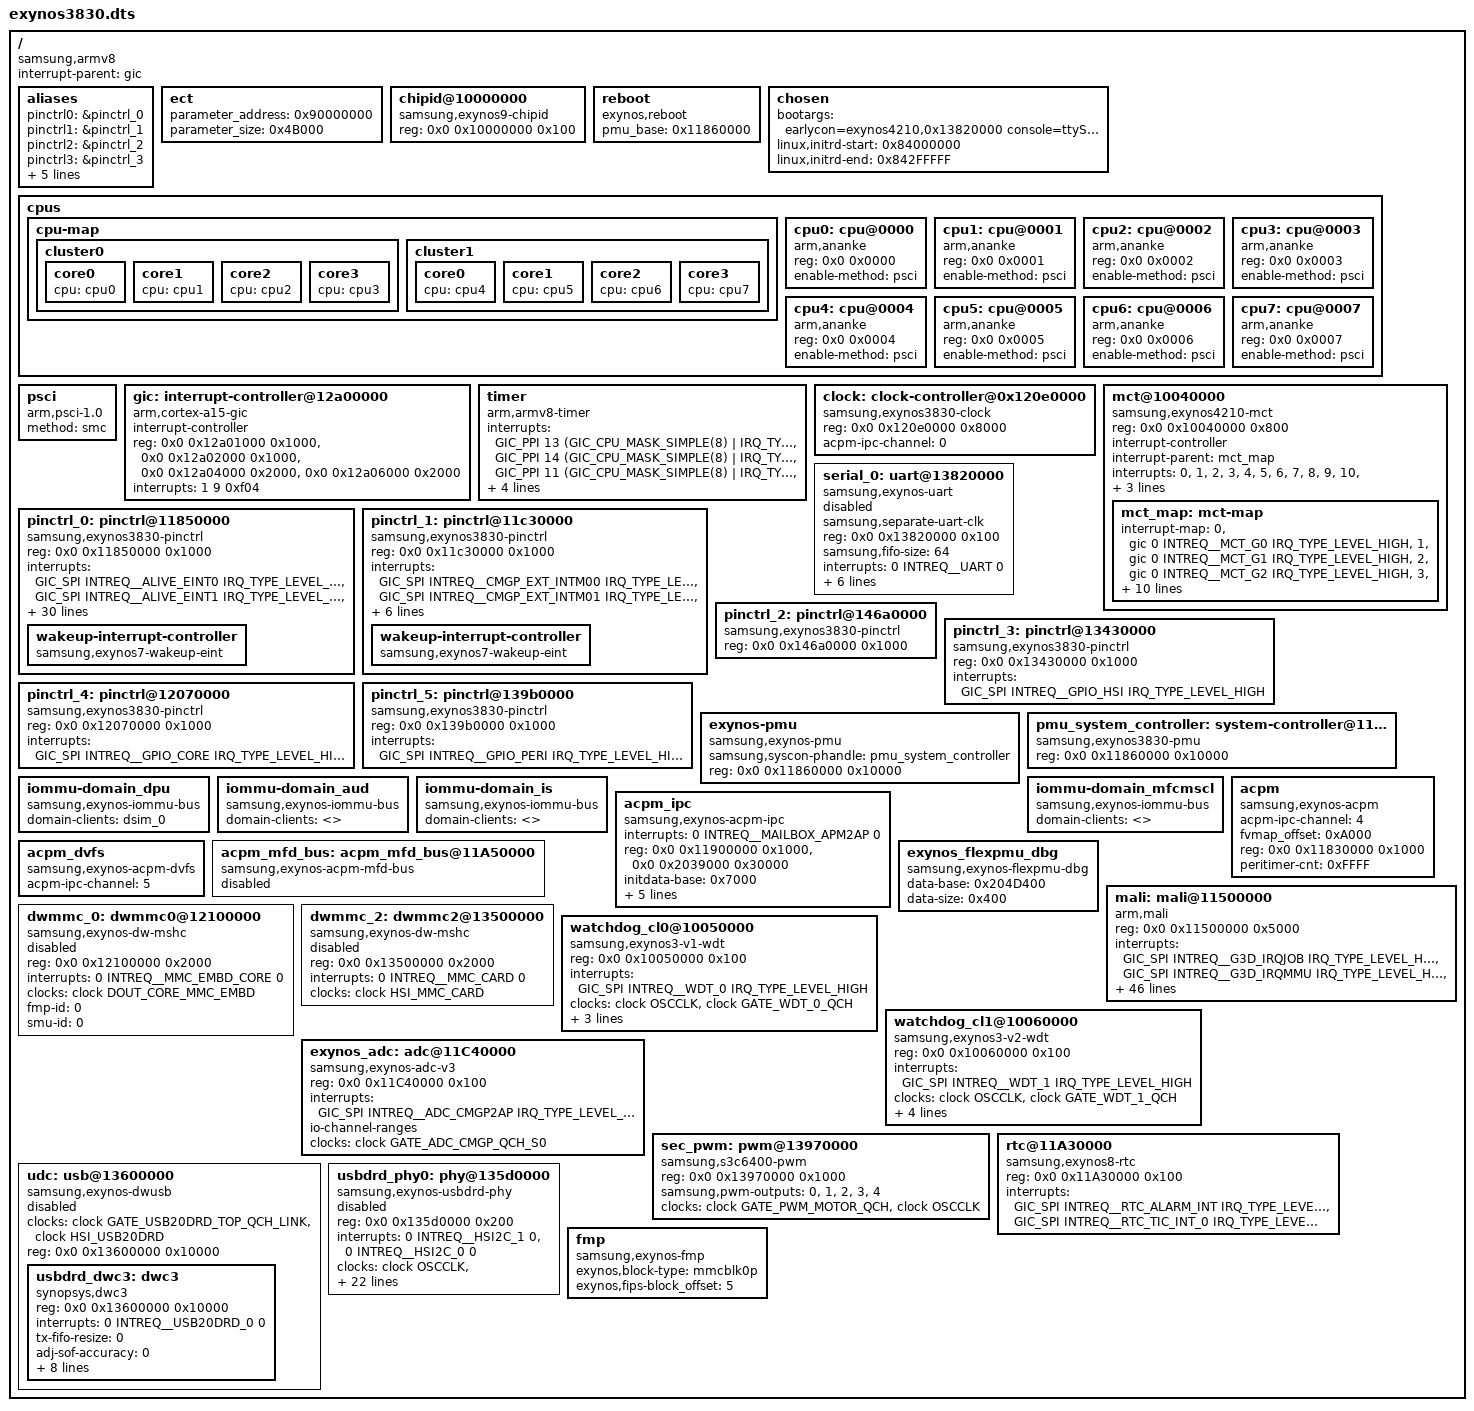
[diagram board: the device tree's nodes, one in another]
/*
 * SAMSUNG EXYNOS3830 SoC device tree source
 *
 * Copyright (c) 2018 Samsung Electronics Co., Ltd.
 *		http://www.samsung.com
 *
 * SAMSUNG EXYNOS3830 SoC device nodes are listed in this file.
 * EXYNOS based board files can include this file and provide
 * values for board specfic bindings.
 *
 * This program is free software; you can redistribute it and/or modify
 * it under the terms of the GNU General Public License version 2 as
 * published by the Free Software Foundation.
 */

/dts-v1/;
#include <dt-bindings/interrupt-controller/arm-gic.h>
#include <dt-bindings/interrupt-controller/exynos3830.h>
#include <dt-bindings/clock/exynos3830.h>
#include "exynos3830-pinctrl.dtsi"
#include "exynos3830-rmem.dtsi"
#include "exynos3830-sysmmu.dtsi"
#include "exynos3830-dpu.dtsi"
#include "exynos3830-usi.dtsi"
#include "exynos3830-debug.dtsi"
#include "exynos3830-pm-domains.dtsi"

/ {
	compatible = "samsung,armv8", "samsung,exynos3830";
	interrupt-parent = <&gic>;
	#address-cells = <2>;
	#size-cells = <1>;

	aliases {
		pinctrl0 = &pinctrl_0;
		pinctrl1 = &pinctrl_1;
		pinctrl2 = &pinctrl_2;
		pinctrl3 = &pinctrl_3;
		pinctrl4 = &pinctrl_4;
		pinctrl5 = &pinctrl_5;
		uart0 = &serial_0;
		mshc0 = &dwmmc_0;
		mshc2 = &dwmmc_2;

	};

	ect {
		parameter_address = <0x90000000>;
		parameter_size = <0x4B000>;
	};

	chipid@10000000 {
		compatible = "samsung,exynos9-chipid";
		reg = <0x0 0x10000000 0x100>;
	};

	reboot {
		compatible = "exynos,reboot";
		pmu_base = <0x11860000>;
	};

	chosen: chosen {
		bootargs = "earlycon=exynos4210,0x13820000 console=ttySAC0,115200n8 androidboot.dtbo_idx=0 skip_initramfs rootwait ro root=/dev/mmcblk0p12 init=/init clk_ignore_unused androidboot.hardware=exynos3830 androidboot.debug_level=0x4948 firmware_class.path=/vendor/firmware";
		//bootargs = "earlycon=exynos4210,0x13820000 console=ttySAC0,115200n8 androidboot.dtbo_idx=0 root=/dev/ram0 rw ramdisk=8192 initrd=0x84000000,8M init=/linuxrc mem=512M clk_ignore_unused";
		linux,initrd-start = <0x84000000>;
		linux,initrd-end = <0x842FFFFF>;
	};

	cpus {
		#address-cells = <2>;
		#size-cells = <0>;

		cpu-map {
			cluster0 {
				core0 {
					cpu = <&cpu0>;
				};
				core1 {
					cpu = <&cpu1>;
				};
				core2 {
					cpu = <&cpu2>;
				};
				core3 {
					cpu = <&cpu3>;
				};
			};

			cluster1 {
				core0 {
					cpu = <&cpu4>;
				};
				core1 {
					cpu = <&cpu5>;
				};
				core2 {
					cpu = <&cpu6>;
				};
				core3 {
					cpu = <&cpu7>;
				};
			};
		};

		cpu0: cpu@0000 {
			device_type = "cpu";
			compatible = "arm,ananke", "arm,armv8";
			reg = <0x0 0x0000>;
			enable-method = "psci";
		//	sched-energy-data = <&ANANKE_ENERGY>;
		//	cpu-idle-states = <&ANANKE_CPU_SLEEP>;
		};
		cpu1: cpu@0001 {
			device_type = "cpu";
			compatible = "arm,ananke", "arm,armv8";
			reg = <0x0 0x0001>;
			enable-method = "psci";
		};
		cpu2: cpu@0002 {
			device_type = "cpu";
			compatible = "arm,ananke", "arm,armv8";
			reg = <0x0 0x0002>;
			enable-method = "psci";
		};
		cpu3: cpu@0003 {
			device_type = "cpu";
			compatible = "arm,ananke", "arm,armv8";
			reg = <0x0 0x0003>;
			enable-method = "psci";
		};
		cpu4: cpu@0004 {
			device_type = "cpu";
			compatible = "arm,ananke", "arm,armv8";
			reg = <0x0 0x0004>;
			enable-method = "psci";
		};
		cpu5: cpu@0005 {
			device_type = "cpu";
			compatible = "arm,ananke", "arm,armv8";
			reg = <0x0 0x0005>;
			enable-method = "psci";
		};
		cpu6: cpu@0006 {
			device_type = "cpu";
			compatible = "arm,ananke", "arm,armv8";
			reg = <0x0 0x0006>;
			enable-method = "psci";
		};
		cpu7: cpu@0007 {
			device_type = "cpu";
			compatible = "arm,ananke", "arm,armv8";
			reg = <0x0 0x0007>;
			enable-method = "psci";
		};
	};

	psci {
		compatible = "arm,psci-1.0";
		method = "smc";
	};

	gic:interrupt-controller@12a00000 {
		compatible = "arm,cortex-a15-gic", "arm,cortex-a9-gic";
		#interrupt-cells = <3>;
		#address-cells = <0>;
		interrupt-controller;
		reg =	<0x0 0x12a01000 0x1000>,
			<0x0 0x12a02000 0x1000>,
			<0x0 0x12a04000 0x2000>,
			<0x0 0x12a06000 0x2000>;
		interrupts = <1 9 0xf04>;
	};

	timer {
	        compatible = "arm,armv8-timer";
		interrupts = <GIC_PPI 13
				(GIC_CPU_MASK_SIMPLE(8) | IRQ_TYPE_LEVEL_LOW)>,
			     <GIC_PPI 14
				(GIC_CPU_MASK_SIMPLE(8) | IRQ_TYPE_LEVEL_LOW)>,
			     <GIC_PPI 11
				(GIC_CPU_MASK_SIMPLE(8) | IRQ_TYPE_LEVEL_LOW)>,
			     <GIC_PPI 10
				(GIC_CPU_MASK_SIMPLE(8) | IRQ_TYPE_LEVEL_LOW)>;
	        clock-frequency = <26000000>;
		use-clocksource-only;
		use-physical-timer;
	};

	clock: clock-controller@0x120e0000 {
		compatible = "samsung,exynos3830-clock";
		reg = <0x0 0x120e0000 0x8000>;
		#clock-cells = <1>;
		acpm-ipc-channel = <0>;
	};

	mct@10040000 {
		compatible = "samsung,exynos4210-mct";
		reg = <0x0 0x10040000 0x800>;
		interrupt-controller;
		#interrupt-cells = <1>;
		interrupt-parent = <&mct_map>;
		interrupts =	<0>, <1>, <2>, <3>,
				<4>, <5>, <6>, <7>,
				<8>, <9>, <10>, <11>;
		clocks = <&clock OSCCLK>, <&clock GATE_MCT_QCH>;
		clock-names = "fin_pll", "mct";
		use-clockevent-only;

		mct_map: mct-map {
			#interrupt-cells = <1>;
			#address-cells = <0>;
			#size-cells = <0>;
			interrupt-map = <0 &gic 0 INTREQ__MCT_G0 IRQ_TYPE_LEVEL_HIGH>,
					<1 &gic 0 INTREQ__MCT_G1 IRQ_TYPE_LEVEL_HIGH>,
					<2 &gic 0 INTREQ__MCT_G2 IRQ_TYPE_LEVEL_HIGH>,
					<3 &gic 0 INTREQ__MCT_G3 IRQ_TYPE_LEVEL_HIGH>,
					<4 &gic 0 INTREQ__MCT_L0 IRQ_TYPE_LEVEL_HIGH>,
					<5 &gic 0 INTREQ__MCT_L1 IRQ_TYPE_LEVEL_HIGH>,
					<6 &gic 0 INTREQ__MCT_L2 IRQ_TYPE_LEVEL_HIGH>,
					<7 &gic 0 INTREQ__MCT_L3 IRQ_TYPE_LEVEL_HIGH>,
					<8 &gic 0 INTREQ__MCT_L4 IRQ_TYPE_LEVEL_HIGH>,
					<9 &gic 0 INTREQ__MCT_L5 IRQ_TYPE_LEVEL_HIGH>,
					<10 &gic 0 INTREQ__MCT_L6 IRQ_TYPE_LEVEL_HIGH>,
					<11 &gic 0 INTREQ__MCT_L7 IRQ_TYPE_LEVEL_HIGH>;
		};
	};

	serial_0: uart@13820000 {
		compatible = "samsung,exynos-uart";
		samsung,separate-uart-clk;
		reg = <0x0 0x13820000 0x100>;
		samsung,fifo-size = <64>;
		interrupts = <0 INTREQ__UART 0>;
		pinctrl-names = "default";
		pinctrl-0 = <&uart0_bus>;
		samsung,usi-serial-v2;
		samsung,dbg-uart-ch;
		samsung,dbg-uart-baud = <115200>;
		samsung,dbg-word-len = <8>;
		clocks = <&clock GATE_UART_QCH>, <&clock DOUT_UART>;
		clock-names = "gate_uart_clk0", "ipclk_uart0";
		status = "disabled";
	};

	/* ALIVE */
	pinctrl_0: pinctrl@11850000 {
		compatible = "samsung,exynos3830-pinctrl";
		reg = <0x0 0x11850000 0x1000>;
		interrupts = <GIC_SPI INTREQ__ALIVE_EINT0 IRQ_TYPE_LEVEL_HIGH>,
			     <GIC_SPI INTREQ__ALIVE_EINT1 IRQ_TYPE_LEVEL_HIGH>,
			     <GIC_SPI INTREQ__ALIVE_EINT2 IRQ_TYPE_LEVEL_HIGH>,
			     <GIC_SPI INTREQ__ALIVE_EINT3 IRQ_TYPE_LEVEL_HIGH>,
			     <GIC_SPI INTREQ__ALIVE_EINT4 IRQ_TYPE_LEVEL_HIGH>,
			     <GIC_SPI INTREQ__ALIVE_EINT5 IRQ_TYPE_LEVEL_HIGH>,
			     <GIC_SPI INTREQ__ALIVE_EINT6 IRQ_TYPE_LEVEL_HIGH>,
			     <GIC_SPI INTREQ__ALIVE_EINT7 IRQ_TYPE_LEVEL_HIGH>,
			     <GIC_SPI INTREQ__ALIVE_EINT8 IRQ_TYPE_LEVEL_HIGH>,
			     <GIC_SPI INTREQ__ALIVE_EINT9 IRQ_TYPE_LEVEL_HIGH>,
			     <GIC_SPI INTREQ__ALIVE_EINT10 IRQ_TYPE_LEVEL_HIGH>,
			     <GIC_SPI INTREQ__ALIVE_EINT11 IRQ_TYPE_LEVEL_HIGH>,
			     <GIC_SPI INTREQ__ALIVE_EINT12 IRQ_TYPE_LEVEL_HIGH>,
			     <GIC_SPI INTREQ__ALIVE_EINT13 IRQ_TYPE_LEVEL_HIGH>,
			     <GIC_SPI INTREQ__ALIVE_EINT14 IRQ_TYPE_LEVEL_HIGH>,
			     <GIC_SPI INTREQ__ALIVE_EINT15 IRQ_TYPE_LEVEL_HIGH>,
			     <GIC_SPI INTREQ__ALIVE_EINT16 IRQ_TYPE_LEVEL_HIGH>,
			     <GIC_SPI INTREQ__ALIVE_EINT17 IRQ_TYPE_LEVEL_HIGH>,
			     <GIC_SPI INTREQ__ALIVE_EINT18 IRQ_TYPE_LEVEL_HIGH>,
			     <GIC_SPI INTREQ__ALIVE_EINT19 IRQ_TYPE_LEVEL_HIGH>,
			     <GIC_SPI INTREQ__ALIVE_EINT20 IRQ_TYPE_LEVEL_HIGH>,
			     <GIC_SPI INTREQ__ALIVE_EINT21 IRQ_TYPE_LEVEL_HIGH>,
			     <GIC_SPI INTREQ__ALIVE_EINT22 IRQ_TYPE_LEVEL_HIGH>,
			     <GIC_SPI INTREQ__ALIVE_EINT23 IRQ_TYPE_LEVEL_HIGH>,
			     <GIC_SPI INTREQ__ALIVE_EINT24 IRQ_TYPE_LEVEL_HIGH>,
			     <GIC_SPI INTREQ__ALIVE_EINT25 IRQ_TYPE_LEVEL_HIGH>,
			     <GIC_SPI INTREQ__ALIVE_EINT26 IRQ_TYPE_LEVEL_HIGH>,
			     <GIC_SPI INTREQ__ALIVE_EINT27 IRQ_TYPE_LEVEL_HIGH>,
			     <GIC_SPI INTREQ__ALIVE_EINT28 IRQ_TYPE_LEVEL_HIGH>,
			     <GIC_SPI INTREQ__ALIVE_EINT29 IRQ_TYPE_LEVEL_HIGH>,
			     <GIC_SPI INTREQ__ALIVE_EINT30 IRQ_TYPE_LEVEL_HIGH>,
			     <GIC_SPI INTREQ__ALIVE_EINT31 IRQ_TYPE_LEVEL_HIGH>;

		wakeup-interrupt-controller {
			compatible = "samsung,exynos7-wakeup-eint";
		};
	};

	/* CMGP */
	pinctrl_1: pinctrl@11c30000 {
		compatible = "samsung,exynos3830-pinctrl";
		reg = <0x0 0x11c30000 0x1000>;
		interrupts = <GIC_SPI INTREQ__CMGP_EXT_INTM00 IRQ_TYPE_LEVEL_HIGH>,
			     <GIC_SPI INTREQ__CMGP_EXT_INTM01 IRQ_TYPE_LEVEL_HIGH>,
			     <GIC_SPI INTREQ__CMGP_EXT_INTM02 IRQ_TYPE_LEVEL_HIGH>,
			     <GIC_SPI INTREQ__CMGP_EXT_INTM03 IRQ_TYPE_LEVEL_HIGH>,
			     <GIC_SPI INTREQ__CMGP_EXT_INTM04 IRQ_TYPE_LEVEL_HIGH>,
			     <GIC_SPI INTREQ__CMGP_EXT_INTM05 IRQ_TYPE_LEVEL_HIGH>,
			     <GIC_SPI INTREQ__CMGP_EXT_INTM06 IRQ_TYPE_LEVEL_HIGH>,
			     <GIC_SPI INTREQ__CMGP_EXT_INTM07 IRQ_TYPE_LEVEL_HIGH>;

		wakeup-interrupt-controller {
			compatible = "samsung,exynos7-wakeup-eint";
		};
	};

	/* AUD */
	pinctrl_2: pinctrl@146a0000 {
		compatible = "samsung,exynos3830-pinctrl";
		reg = <0x0 0x146a0000 0x1000>;
	};

	/* HSI */
	pinctrl_3: pinctrl@13430000 {
		compatible = "samsung,exynos3830-pinctrl";
		reg = <0x0 0x13430000 0x1000>;
		interrupts = <GIC_SPI INTREQ__GPIO_HSI IRQ_TYPE_LEVEL_HIGH>;
	};

	/* CORE */
	pinctrl_4: pinctrl@12070000 {
		compatible = "samsung,exynos3830-pinctrl";
		reg = <0x0 0x12070000 0x1000>;
		interrupts = <GIC_SPI INTREQ__GPIO_CORE IRQ_TYPE_LEVEL_HIGH>;
	};

	/* PERI */
	pinctrl_5: pinctrl@139b0000 {
		compatible = "samsung,exynos3830-pinctrl";
		reg = <0x0 0x139b0000 0x1000>;
		interrupts = <GIC_SPI INTREQ__GPIO_PERI IRQ_TYPE_LEVEL_HIGH>;
	};

	exynos-pmu {
		compatible = "samsung,exynos-pmu";
		samsung,syscon-phandle = <&pmu_system_controller>;
		reg = <0x0 0x11860000 0x10000>;
		reg-names = "pmu_alive";
	};

	pmu_system_controller: system-controller@11860000 {
		compatible = "samsung,exynos3830-pmu", "syscon";
		reg = <0x0 0x11860000 0x10000>;
	};

	iommu-domain_dpu {
		compatible = "samsung,exynos-iommu-bus";
		#address-cells = <2>;
		#size-cells = <1>;
		ranges;

		domain-clients = <&dsim_0>;
	};

	iommu-domain_aud {
		compatible = "samsung,exynos-iommu-bus";
		#address-cells = <2>;
		#size-cells = <1>;
		ranges;

		domain-clients = <>;
	};

	iommu-domain_is {
		compatible = "samsung,exynos-iommu-bus";
		#address-cells = <2>;
		#size-cells = <1>;
		ranges;

		domain-clients = <>;
	};

	iommu-domain_mfcmscl {
		compatible = "samsung,exynos-iommu-bus";
		#address-cells = <2>;
		#size-cells = <1>;
		ranges;

		domain-clients = <>;
	};

	acpm {
		compatible = "samsung,exynos-acpm";
		#address-cells = <2>;
		#size-cells = <1>;
		acpm-ipc-channel = <4>;
		fvmap_offset = <0xA000>;
		reg = <0x0 0x11830000 0x1000>;		/* TIMER_APM */
		reg-names = "timer_apm";
		peritimer-cnt = <0xFFFF>;
	};

	acpm_ipc {
		compatible = "samsung,exynos-acpm-ipc";
		#address-cells = <2>;
		#size-cells = <1>;
		interrupts = <0 INTREQ__MAILBOX_APM2AP 0>;	/* AP2APM MAILBOX SPI NUM*/
		reg = <0x0 0x11900000 0x1000>,		/* AP2APM MAILBOX */
			<0x0 0x2039000 0x30000>;	/* APM SRAM */
		initdata-base = <0x7000>;
		num-timestamps = <32>;
		debug-log-level = <0>;
		logging-period = <500>;
		dump-base = <0x203C000>;
		dump-size = <0x2D000>;			/* 180KB */
	};

	acpm_dvfs {
		compatible = "samsung,exynos-acpm-dvfs";
		acpm-ipc-channel = <5>;
	};

	acpm_mfd_bus: acpm_mfd_bus@11A50000 {
		compatible = "samsung,exynos-acpm-mfd-bus";
		status = "disabled";
	};

	exynos_flexpmu_dbg {
		compatible = "samsung,exynos-flexpmu-dbg";
		#address-cells = <2>;
		#size-cells = <1>;
		data-base = <0x204D400>;
		data-size = <0x400>;
	};

    /* mali */
    mali: mali@11500000 {
        compatible = "arm,mali";
        reg = <0x0 0x11500000 0x5000>;
        interrupts = <GIC_SPI INTREQ__G3D_IRQJOB IRQ_TYPE_LEVEL_HIGH>,
                   <GIC_SPI INTREQ__G3D_IRQMMU IRQ_TYPE_LEVEL_HIGH>,
                   <GIC_SPI INTREQ__G3D_IRQGPU IRQ_TYPE_LEVEL_HIGH>;
        interrupt-names = "JOB", "MMU", "GPU";
        g3d_cmu_cal_id = <ACPM_DVFS_G3D>;
        /*samsung,power-domain = <&pd_g3d>; Please enable this when pm-domain is updated.*/
        g3d_genpd_name = "pd-g3d";
        #cooling-cells = <2>; /* min followed by max */
        governor = "interactive";
        interactive_info = <377000 75 0>;
        gpu_dvfs_table_size = <10 7>; /*<row col>*/
        /*  8 columns          freq  down   up stay     mif  little     big  */
        gpu_dvfs_table = <  1105000    95  100   1  2093000 1794000       0
                            1053000    80   90   1  2093000 1794000       0
                             949000    56   90   1  2093000 1794000       0
                             858000    58   90   1  2093000 1794000       0
                             754000    90  100   5  1794000 1508000       0
                             650000    70   90   4  1539000 1378000       0
                             546000    58   80   1  1539000 1378000       0
                             455000    55   70   1   676000  806000       0
                             377000    48   70   1   546000  546000       0
                             260000     0   70   1   421000  442000       0 >;
        gpu_sustainable_info = <0 0 0 0 0>;
        gpu_pmqos_cpu_cluster_num = <2>;
        gpu_pmu_status_reg_offset = <0x1f04>;
        gpu_pmu_status_local_pwr_mask = <0x1>; /*0x1 << 0*/
        gpu_max_clock = <754000>;
        gpu_max_clock_limit = <754000>;
        gpu_min_clock = <260000>;
        gpu_dvfs_start_clock = <260000>;
        gpu_dvfs_bl_config_clock = <260000>;
        gpu_default_voltage = <800000>;
        gpu_cold_minimum_vol = <0>;
        gpu_voltage_offset_margin = <37500>;
        gpu_tmu_control = <1>;
        gpu_temp_throttling_level_num = <5>;
        gpu_temp_throttling = <650000 546000 455000 377000 260000>;
        gpu_power_coeff = <625>;
        gpu_dvfs_time_interval = <5>; /*1 tick : 10ms*/
        gpu_default_wakeup_lock = <1>;
        gpu_dynamic_abb = <0>;
        gpu_early_clk_gating = <0>;
        gpu_dvs = <0>;
        gpu_inter_frame_pm = <0>;
        gpu_perf_gathering = <0>;
        gpu_runtime_pm_delay_time = <50>;
        gpu_dvfs_polling_time = <30>;
        gpu_pmqos_int_disable = <1>;
        gpu_pmqos_mif_max_clock = <2094000>;
        gpu_pmqos_mif_max_clock_base = <650000>;
        gpu_cl_dvfs_start_base = <377000>;
        gpu_debug_level = <3>; /*DEBUG(1) INFO(2) WARNING(3) ERROR(4)*/
        gpu_trace_level = <8>; /*TRACE_ALL*/
        gpu_mo_min_clock = <377000>;
        gpu_boost_gpu_min_lock = <0>;
        gpu_boost_egl_min_lock = <1872000>;
        gpu_vk_boost_max_lock = <325000>;
        gpu_vk_boost_mif_min_lock = <1014000>;
        gpu_bts_support = <1>;
    };

	dwmmc_0: dwmmc0@12100000 {
		compatible = "samsung,exynos-dw-mshc";
		reg = <0x0 0x12100000 0x2000>;
		reg-names = "dw_mmc";
		interrupts = <0 INTREQ__MMC_EMBD_CORE 0>;
		#address-cells = <1>;
		#size-cells = <0>;
		clocks = <&clock DOUT_CORE_MMC_EMBD>;
		clock-names = "ciu";
		status = "disabled";
		fmp-id = <0>;
		smu-id = <0>;
	 };

	dwmmc_2: dwmmc2@13500000 {
		compatible = "samsung,exynos-dw-mshc";
		reg = <0x0 0x13500000 0x2000>;
		reg-names = "dw_mmc";
		interrupts = <0 INTREQ__MMC_CARD 0>;
		#address-cells = <1>;
		#size-cells = <0>;
		clocks = <&clock HSI_MMC_CARD>;
		clock-names = "ciu";
		status = "disabled";
	 };

	watchdog_cl0@10050000 {
		compatible = "samsung,exynos3-v1-wdt";
		reg = <0x0 0x10050000 0x100>;
		interrupts = <GIC_SPI INTREQ__WDT_0 IRQ_TYPE_LEVEL_HIGH>;
		clocks = <&clock OSCCLK>, <&clock GATE_WDT_0_QCH>;
		clock-names = "rate_watchdog", "gate_watchdog";
		timeout-sec = <30>;
		samsung,syscon-phandle = <&pmu_system_controller>;
		index = <0>; /* if little cluster then index is 0*/
	};

	watchdog_cl1@10060000 {
		compatible = "samsung,exynos3-v2-wdt";
		reg = <0x0 0x10060000 0x100>;
		interrupts = <GIC_SPI INTREQ__WDT_1 IRQ_TYPE_LEVEL_HIGH>;
		clocks = <&clock OSCCLK>, <&clock GATE_WDT_1_QCH>;
		clock-names = "rate_watchdog", "gate_watchdog";
		timeout-sec = <30>;
		samsung,syscon-phandle = <&pmu_system_controller>;
		index = <1>; /* if little cluster then index is 0*/
		use_multistage_wdt; /* Use FIQ debug watchdog */
	};

	exynos_adc: adc@11C40000 {
		compatible = "samsung,exynos-adc-v3";
		reg = <0x0 0x11C40000 0x100>;
		interrupts = <GIC_SPI INTREQ__ADC_CMGP2AP IRQ_TYPE_LEVEL_HIGH>;
		#io-channel-cells = <1>;
		io-channel-ranges;
		clocks = <&clock GATE_ADC_CMGP_QCH_S0>;
		clock-names = "gate_adcif";
	};

	sec_pwm: pwm@13970000 {
		compatible = "samsung,s3c6400-pwm";
		reg = <0x0 0x13970000 0x1000>;
		samsung,pwm-outputs = <0>, <1>, <2>, <3>, <4>;
		#pwm-cells = <3>;
		clocks = <&clock GATE_PWM_MOTOR_QCH>, <&clock OSCCLK>;
		clock-names = "pwm_pclk", "pwm_sclk";
		status = "ok";
	};

	rtc@11A30000 {
		compatible = "samsung,exynos8-rtc";
		reg = <0x0 0x11A30000 0x100>;
		interrupts = <GIC_SPI INTREQ__RTC_ALARM_INT IRQ_TYPE_LEVEL_HIGH>,
			     <GIC_SPI INTREQ__RTC_TIC_INT_0 IRQ_TYPE_LEVEL_HIGH>;
	};

	udc: usb@13600000 {
		compatible = "samsung,exynos-dwusb";
		clocks = <&clock GATE_USB20DRD_TOP_QCH_LINK>, <&clock HSI_USB20DRD>;
		clock-names = "aclk", "sclk";
		reg = <0x0 0x13600000 0x10000>;
		#address-cells = <2>;
		#size-cells = <1>;
		ranges;
		//samsung,power-domain = <&pd_usb>;
		status = "disabled";

		usbdrd_dwc3: dwc3 {
			compatible = "synopsys,dwc3";
			reg = <0x0 0x13600000 0x10000>;
			interrupts = <0 INTREQ__USB20DRD_0 0>;
			tx-fifo-resize = <0>;
			adj-sof-accuracy = <0>;
			is_not_vbus_pad = <1>;
			enable_sprs_transfer = <1>;
			phys = <&usbdrd_phy0 0>, <&usbdrd_phy0 1>;
			phy-names = "usb2-phy", "usb3-phy";
			/* check susphy support */
			xhci_l2_support = <0>;
			/* support usb audio offloading: 1, if not: 0 */
			usb_audio_offloading = <0>;
			//abox = <&abox>; /* Temporary block */
			/* support USB L2 sleep */
			 ldos = <3>;
			ldo_number = <1 2 11>;
			/* INT min lock support */
			usb-pm-qos-int = <400000>;
		};
	};

	usbdrd_phy0: phy@135d0000 {
		compatible = "samsung,exynos-usbdrd-phy";
		reg = <0x0 0x135d0000 0x200>;
		interrupts = <0 INTREQ__HSI2C_1 0>,
			     <0 INTREQ__HSI2C_0 0>;
		clocks = <&clock OSCCLK>, <&clock GATE_USB20DRD_TOP_QCH_LINK>;
		clock-names = "ext_xtal", "aclk";
		samsung,pmu-syscon = <&pmu_system_controller>;
		pmu_mask = <0x0>;
		pmu_offset = <0x704>;
		pmu_offset_dp = <0x704>;

		/* USBDP combo phy version  - 0x200 */
		phy_version = <0x301>;
		/* if it doesn't need phy user mux, */
		/*  you should write "none" */
		/*  but refclk shouldn't be omitted */
		phyclk_mux = "none";
		phy_refclk = "ext_xtal";

		/* if Main phy has the other phy, it must be set to 1. jusf for usbphy_info */
		has_other_phy = <0>;
		/* if combo phy is used, it must be set to 1. usbphy_sub_info is enabled */
		has_combo_phy = <0>;
		sub_phy_version = <0x400>;

		/* ip type */
		/* USB3DRD = 0 */
		/*  USB3HOST = 1 */
		/*  USB2DRD = 2 */
		/*  USB2HOST = 3 */
		ip_type = <0x0>;

		/* for PHY CAL */
		/* choice only one item */
		phy_refsel_clockcore = <1>;
		phy_refsel_ext_osc = <0>;
		phy_refsel_xtal = <0>;
		phy_refsel_diff_pad = <0>;
		phy_refsel_diff_internal = <0>;
		phy_refsel_diff_single = <0>;

		/* true : 1 , false : 0 */
		use_io_for_ovc = <0>;
		common_block_disable = <1>;
		is_not_vbus_pad = <1>;
		used_phy_port = <0>;

		status = "disabled";

		#phy-cells = <1>;
		ranges;
       };

	fmp: fmp {
		compatible = "samsung,exynos-fmp";
		exynos,block-type = "mmcblk0p";
		exynos,fips-block_offset = <5>;
	};
};
